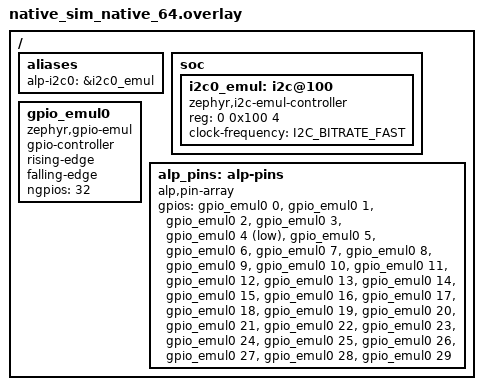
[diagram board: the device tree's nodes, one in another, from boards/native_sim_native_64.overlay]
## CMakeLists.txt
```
# SPDX-License-Identifier: Apache-2.0

cmake_minimum_required(VERSION 3.20)

# board.yaml -> build/generated/alp.conf at configure time, layered
# over prj.conf via EXTRA_CONF_FILE.  Both the emit and the append
# MUST happen before find_package(Zephyr) -- cmake/alp.cmake documents
# why, and the ALP_SDK_ROOT contract a copied-out project relies on.
if(DEFINED ENV{ALP_SDK_ROOT})
    set(ALP_SDK_ROOT $ENV{ALP_SDK_ROOT})
else()
    get_filename_component(ALP_SDK_ROOT ${CMAKE_CURRENT_SOURCE_DIR}/../../.. ABSOLUTE)
endif()
include(${ALP_SDK_ROOT}/cmake/alp.cmake)

alp_sdk_zephyr_conf(m33_sm)

find_package(Zephyr REQUIRED HINTS $ENV{ZEPHYR_BASE})
project(iot_connected_camera LANGUAGES C)

target_sources(app PRIVATE src/main.c)
```

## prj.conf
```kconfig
# SPDX-License-Identifier: Apache-2.0
#
# Intentionally empty.  Every CONFIG_* this app needs is derived
# from board.yaml by `tan build` and layered in via
# EXTRA_CONF_FILE (see scripts/gen_example_alp_conf.py).  The optional overlay
# `overlay-aen.conf` carries the v0.3 IoT stack enables; load it
# explicitly with `west build -- --extra-conf-file overlay-aen.conf`
# when targeting a real board with Wi-Fi up.

# App-specific stack tuning -- the v0.3 IoT path runs supplicant +
# mqtt loops on `main`'s frame.  Tuning, not feature-select.
CONFIG_MAIN_STACK_SIZE=4096
```

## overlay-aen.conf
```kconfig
# SPDX-License-Identifier: Apache-2.0
#
# AEN-Zephyr overlay -- enables the real Wi-Fi station + MQTT path
# for E1M-AEN family SoMs.  Layered on top of the base prj.conf via
# `west build -- -DEXTRA_CONF_FILE=overlay-aen.conf` (or twister's
# extra_args block in testcase.yaml when the EVK board file lands).
#
# native_sim builds keep the base prj.conf only -- there is no
# Wi-Fi radio under the simulator and the wrapper falls back to the
# documented NULL-with-NOSUPPORT contract.

# Networking core
CONFIG_NETWORKING=y
CONFIG_NET_TCP=y
CONFIG_NET_IPV4=y
CONFIG_NET_DHCPV4=y
CONFIG_NET_MGMT=y
CONFIG_NET_MGMT_EVENT=y
CONFIG_NET_SOCKETS=y

# Wi-Fi station (E1M-AEN ships TI CC3501E or Murata LBEE5HY2FY).
# WPA-supplicant is the upstream Zephyr Wi-Fi management default.
CONFIG_WIFI=y
CONFIG_WIFI_NM_WPA_SUPPLICANT=y

# MQTT (over plain TCP in v0.2; TLS lands with <alp/security.h> v0.3).
CONFIG_MQTT_LIB=y

# Wrapper toggles -- both default y under their CONFIG_ deps but
# spelling them out makes the intent visible to a reader who comes
# in cold.
CONFIG_ALP_SDK_IOT_WIFI=y
CONFIG_ALP_SDK_IOT_MQTT=y

# Larger main stack to absorb the Wi-Fi supplicant + mqtt loop
# threads' frames.
CONFIG_MAIN_STACK_SIZE=8192
```

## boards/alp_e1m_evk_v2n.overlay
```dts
/*
 * Copyright 2026 Alp Lab AB
 * SPDX-License-Identifier: Apache-2.0
 *
 * IoT connected-camera -- overlay for the E1M EVK populated with an
 * E1M-V2N101 / E1M-V2N102 SoM.  Re-aliases what the board file
 * exposes: alp_i2c0 (SSD1306 status pane), alp_uart0 (console), and
 * the standard POSITIONAL alp,pin-array.
 *
 * The alp,pin-array is POSITIONAL: alp_z_gpio_resolve(pin_id) indexes
 * it by the E1M GPIO index, so entry N is E1M pad N in the
 * e1m_pinout.h canonical order (IO0..IO25 = 0..25, PWM0..PWM7 =
 * 26..33, ...).  The EVK's RGB LED sits on PWM pads, so the status
 * LED is driven through a pad's GPIO-secondary index (ALP_E1M_GPIO_PWM3).
 * This overlay covers indices 0..29 -- the capture trigger is at [4]
 * and the RGB-red status LED at [29].  The EVK is shared between the
 * AEN and V2N families; only the silicon behind each pad changes.
 *
 * The authoritative alp_e1m_evk_v2n board file lives in
 * alplabai/alp-zephyr-modules (TBD); until it ships, twister excludes
 * the V2N target from the example (see testcase.yaml).
 */

#include <zephyr/dt-bindings/gpio/gpio.h>

/ {
    aliases {
        alp-i2c0  = &i2c0;       /* EVK sensor bus (SSD1306 status pane) */
        alp-uart0 = &uart0;      /* console / JTAG-side debug UART */
    };

    /* Positional alp,pin-array (e1m_pinout.h canonical order).  Only
     * the indices this demo routes carry a meaningful net; the rest
     * are placeholders so the positional index stays stable.  The gpio
     * bank/pin numbers are PLACEHOLDERS (see NOTE below). */
    alp_pins: alp-pins {
        compatible = "alp,pin-array";
        gpios = <&gpio0  0 GPIO_ACTIVE_HIGH>,                            /* [ 0] ALP_E1M_GPIO_IO0  (unrouted placeholder) */
                <&gpio0  1 GPIO_ACTIVE_HIGH>,                            /* [ 1] ALP_E1M_GPIO_IO1  (unrouted placeholder) */
                <&gpio0  2 GPIO_ACTIVE_HIGH>,                            /* [ 2] ALP_E1M_GPIO_IO2  (unrouted placeholder) */
                <&gpio0  3 GPIO_ACTIVE_HIGH>,                            /* [ 3] ALP_E1M_GPIO_IO3  (unrouted placeholder) */
                <&gpio1  0 (GPIO_ACTIVE_LOW | GPIO_PULL_UP)>,           /* [ 4] ALP_E1M_GPIO_IO4  -- capture trigger (encoder switch) */
                <&gpio0  5 GPIO_ACTIVE_HIGH>,                            /* [ 5] ALP_E1M_GPIO_IO5  (unrouted placeholder) */
                <&gpio0  6 GPIO_ACTIVE_HIGH>,                            /* [ 6] ALP_E1M_GPIO_IO6  (unrouted placeholder) */
                <&gpio0  7 GPIO_ACTIVE_HIGH>,                            /* [ 7] ALP_E1M_GPIO_IO7  (unrouted placeholder) */
                <&gpio0  8 GPIO_ACTIVE_HIGH>,                            /* [ 8] ALP_E1M_GPIO_IO8  (unrouted placeholder) */
                <&gpio0  9 GPIO_ACTIVE_HIGH>,                            /* [ 9] ALP_E1M_GPIO_IO9  (unrouted placeholder) */
                <&gpio0 10 GPIO_ACTIVE_HIGH>,                            /* [10] ALP_E1M_GPIO_IO10 (unrouted placeholder) */
                <&gpio0 11 GPIO_ACTIVE_HIGH>,                            /* [11] ALP_E1M_GPIO_IO11 (unrouted placeholder) */
                <&gpio0 12 GPIO_ACTIVE_HIGH>,                            /* [12] ALP_E1M_GPIO_IO12 (unrouted placeholder) */
                <&gpio0 13 GPIO_ACTIVE_HIGH>,                            /* [13] ALP_E1M_GPIO_IO13 (unrouted placeholder) */
                <&gpio0 14 GPIO_ACTIVE_HIGH>,                            /* [14] ALP_E1M_GPIO_IO14 (unrouted placeholder) */
                <&gpio0 15 GPIO_ACTIVE_HIGH>,                            /* [15] ALP_E1M_GPIO_IO15 (unrouted placeholder) */
                <&gpio0 16 GPIO_ACTIVE_HIGH>,                            /* [16] ALP_E1M_GPIO_IO16 (unrouted placeholder) */
                <&gpio0 17 GPIO_ACTIVE_HIGH>,                            /* [17] ALP_E1M_GPIO_IO17 (unrouted placeholder) */
                <&gpio0 18 GPIO_ACTIVE_HIGH>,                            /* [18] ALP_E1M_GPIO_IO18 (unrouted placeholder) */
                <&gpio0 19 GPIO_ACTIVE_HIGH>,                            /* [19] ALP_E1M_GPIO_IO19 (unrouted placeholder) */
                <&gpio0 20 GPIO_ACTIVE_HIGH>,                            /* [20] ALP_E1M_GPIO_IO20 (unrouted placeholder) */
                <&gpio0 21 GPIO_ACTIVE_HIGH>,                            /* [21] ALP_E1M_GPIO_IO21 (unrouted placeholder) */
                <&gpio0 22 GPIO_ACTIVE_HIGH>,                            /* [22] ALP_E1M_GPIO_IO22 (unrouted placeholder) */
                <&gpio0 23 GPIO_ACTIVE_HIGH>,                            /* [23] ALP_E1M_GPIO_IO23 (unrouted placeholder) */
                <&gpio0 24 GPIO_ACTIVE_HIGH>,                            /* [24] ALP_E1M_GPIO_IO24 (unrouted placeholder) */
                <&gpio0 25 GPIO_ACTIVE_HIGH>,                            /* [25] ALP_E1M_GPIO_IO25 (unrouted placeholder) */
                <&gpio0 26 GPIO_ACTIVE_HIGH>,                            /* [26] ALP_E1M_GPIO_PWM0 -- RGB LED green pad as GPIO */
                <&gpio0 27 GPIO_ACTIVE_HIGH>,                            /* [27] ALP_E1M_GPIO_PWM1 -- RGB LED blue pad as GPIO */
                <&gpio0 28 GPIO_ACTIVE_HIGH>,                            /* [28] ALP_E1M_GPIO_PWM2 (unrouted placeholder) */
                <&gpio1  1 GPIO_ACTIVE_HIGH>;                            /* [29] ALP_E1M_GPIO_PWM3 -- status LED (RGB-red pad as GPIO) */
    };
};

/*
 * NOTE -- gpio bank/pin numbers in the gpios property above are
 * PLACEHOLDERS.  The authoritative mapping lands when
 * alplabai/alp-zephyr-modules publishes the alp_e1m_evk_v2n board
 * file with a pinctrl group naming the exact gpio bank/index for each
 * EVK net (RGB LED on the PWM pads, encoder switch).  The POSITIONAL
 * INDEX (the [NN] in each comment) is the stable ABI; only the
 * <&gpioX Y> columns are TBD.
 */
```

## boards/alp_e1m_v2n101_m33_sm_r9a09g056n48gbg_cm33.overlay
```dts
/*
 * Copyright 2026 Alp Lab AB
 * SPDX-License-Identifier: Apache-2.0
 *
 * IoT connected-camera -- overlay for the E1M EVK populated with an
 * E1M-V2N101 / E1M-V2N102 SoM.  Re-aliases what the board file
 * exposes: alp_i2c0 (SSD1306 status pane), alp_uart0 (console), and
 * the standard POSITIONAL alp,pin-array.
 *
 * The alp,pin-array is POSITIONAL: alp_z_gpio_resolve(pin_id) indexes
 * it by the E1M GPIO index, so entry N is E1M pad N in the
 * e1m_pinout.h canonical order (IO0..IO25 = 0..25, PWM0..PWM7 =
 * 26..33, ...).  The EVK's RGB LED sits on PWM pads, so the status
 * LED is driven through a pad's GPIO-secondary index (ALP_E1M_GPIO_PWM3).
 * This overlay covers indices 0..29 -- the capture trigger is at [4]
 * and the RGB-red status LED at [29].  The EVK is shared between the
 * AEN and V2N families; only the silicon behind each pad changes.
 *
 * The authoritative alp_e1m_v2n101_m33_sm board file ships in-tree at
 * zephyr/boards/alp/e1m_v2n101_m33_sm/; the HW-in-loop scenario stays
 * parked pending twister CI wiring (see testcase.yaml).
 */

#include <zephyr/dt-bindings/gpio/gpio.h>

/ {
    aliases {
        alp-i2c0  = &i2c0;       /* EVK sensor bus (SSD1306 status pane) */
        alp-uart0 = &uart0;      /* console / JTAG-side debug UART */
    };

    /* Positional alp,pin-array (e1m_pinout.h canonical order).  Only
     * the indices this demo routes carry a meaningful net; the rest
     * are placeholders so the positional index stays stable.  The gpio
     * bank/pin numbers are PLACEHOLDERS (see NOTE below). */
    alp_pins: alp-pins {
        compatible = "alp,pin-array";
        gpios = <&gpio0  0 GPIO_ACTIVE_HIGH>,                            /* [ 0] ALP_E1M_GPIO_IO0  (unrouted placeholder) */
                <&gpio0  1 GPIO_ACTIVE_HIGH>,                            /* [ 1] ALP_E1M_GPIO_IO1  (unrouted placeholder) */
                <&gpio0  2 GPIO_ACTIVE_HIGH>,                            /* [ 2] ALP_E1M_GPIO_IO2  (unrouted placeholder) */
                <&gpio0  3 GPIO_ACTIVE_HIGH>,                            /* [ 3] ALP_E1M_GPIO_IO3  (unrouted placeholder) */
                <&gpio1  0 (GPIO_ACTIVE_LOW | GPIO_PULL_UP)>,           /* [ 4] ALP_E1M_GPIO_IO4  -- capture trigger (encoder switch) */
                <&gpio0  5 GPIO_ACTIVE_HIGH>,                            /* [ 5] ALP_E1M_GPIO_IO5  (unrouted placeholder) */
                <&gpio0  6 GPIO_ACTIVE_HIGH>,                            /* [ 6] ALP_E1M_GPIO_IO6  (unrouted placeholder) */
                <&gpio0  7 GPIO_ACTIVE_HIGH>,                            /* [ 7] ALP_E1M_GPIO_IO7  (unrouted placeholder) */
                <&gpio0  8 GPIO_ACTIVE_HIGH>,                            /* [ 8] ALP_E1M_GPIO_IO8  (unrouted placeholder) */
                <&gpio0  9 GPIO_ACTIVE_HIGH>,                            /* [ 9] ALP_E1M_GPIO_IO9  (unrouted placeholder) */
                <&gpio0 10 GPIO_ACTIVE_HIGH>,                            /* [10] ALP_E1M_GPIO_IO10 (unrouted placeholder) */
                <&gpio0 11 GPIO_ACTIVE_HIGH>,                            /* [11] ALP_E1M_GPIO_IO11 (unrouted placeholder) */
                <&gpio0 12 GPIO_ACTIVE_HIGH>,                            /* [12] ALP_E1M_GPIO_IO12 (unrouted placeholder) */
                <&gpio0 13 GPIO_ACTIVE_HIGH>,                            /* [13] ALP_E1M_GPIO_IO13 (unrouted placeholder) */
                <&gpio0 14 GPIO_ACTIVE_HIGH>,                            /* [14] ALP_E1M_GPIO_IO14 (unrouted placeholder) */
                <&gpio0 15 GPIO_ACTIVE_HIGH>,                            /* [15] ALP_E1M_GPIO_IO15 (unrouted placeholder) */
                <&gpio0 16 GPIO_ACTIVE_HIGH>,                            /* [16] ALP_E1M_GPIO_IO16 (unrouted placeholder) */
                <&gpio0 17 GPIO_ACTIVE_HIGH>,                            /* [17] ALP_E1M_GPIO_IO17 (unrouted placeholder) */
                <&gpio0 18 GPIO_ACTIVE_HIGH>,                            /* [18] ALP_E1M_GPIO_IO18 (unrouted placeholder) */
                <&gpio0 19 GPIO_ACTIVE_HIGH>,                            /* [19] ALP_E1M_GPIO_IO19 (unrouted placeholder) */
                <&gpio0 20 GPIO_ACTIVE_HIGH>,                            /* [20] ALP_E1M_GPIO_IO20 (unrouted placeholder) */
                <&gpio0 21 GPIO_ACTIVE_HIGH>,                            /* [21] ALP_E1M_GPIO_IO21 (unrouted placeholder) */
                <&gpio0 22 GPIO_ACTIVE_HIGH>,                            /* [22] ALP_E1M_GPIO_IO22 (unrouted placeholder) */
                <&gpio0 23 GPIO_ACTIVE_HIGH>,                            /* [23] ALP_E1M_GPIO_IO23 (unrouted placeholder) */
                <&gpio0 24 GPIO_ACTIVE_HIGH>,                            /* [24] ALP_E1M_GPIO_IO24 (unrouted placeholder) */
                <&gpio0 25 GPIO_ACTIVE_HIGH>,                            /* [25] ALP_E1M_GPIO_IO25 (unrouted placeholder) */
                <&gpio0 26 GPIO_ACTIVE_HIGH>,                            /* [26] ALP_E1M_GPIO_PWM0 -- RGB LED green pad as GPIO */
                <&gpio0 27 GPIO_ACTIVE_HIGH>,                            /* [27] ALP_E1M_GPIO_PWM1 -- RGB LED blue pad as GPIO */
                <&gpio0 28 GPIO_ACTIVE_HIGH>,                            /* [28] ALP_E1M_GPIO_PWM2 (unrouted placeholder) */
                <&gpio1  1 GPIO_ACTIVE_HIGH>;                            /* [29] ALP_E1M_GPIO_PWM3 -- status LED (RGB-red pad as GPIO) */
    };
};

/*
 * NOTE -- gpio bank/pin numbers in the gpios property above are
 * PLACEHOLDERS.  The authoritative mapping lands when the
 * alp_e1m_v2n101_m33_sm board file (zephyr/boards/alp/e1m_v2n101_m33_sm/)
 * grows a pinctrl group naming the exact gpio bank/index for each
 * EVK net (RGB LED on the PWM pads, encoder switch).  The POSITIONAL
 * INDEX (the [NN] in each comment) is the stable ABI; only the
 * <&gpioX Y> columns are TBD.
 */
```

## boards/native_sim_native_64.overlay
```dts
/*
 * Copyright 2026 Alp Lab AB
 * SPDX-License-Identifier: Apache-2.0
 *
 * Host-build overlay for the IoT connected-camera skeleton.  One
 * emulated I2C bus (SSD1306 status pane) plus the standard
 * alp,pin-array.  Networking is simulated via Zephyr's net stack on
 * native_sim when v0.3 lands; the v0.1 host build leaves it off.
 *
 * The alp,pin-array is POSITIONAL: alp_z_gpio_resolve(pin_id) indexes
 * it by the E1M GPIO index, so entry N must be E1M pad N in the
 * e1m_pinout.h canonical order (IO0..IO25 = 0..25, PWM0..PWM7 =
 * 26..33, ...).  This demo touches two pads through the button_led
 * block:
 *   - index  4 = ALP_E1M_GPIO_IO4   -- capture trigger (encoder switch)
 *   - index 29 = ALP_E1M_GPIO_PWM3  -- status LED, the RGB-red PWM pad
 *                claimed as a plain GPIO (the e1m-spec "GPIO
 *                secondary").
 *
 * Unlike the EVK-targeted demos, this app opens its pads by raw E1M
 * IDs rather than EVK_* macros: its target carrier's pad routes are
 * still TBD pending the schematic, so there is no board routes header
 * to name them yet.
 *
 * (gpio-emul controllers cap at 32 pins; native_sim only needs the
 * range this demo touches, indices 0..29.)
 */

#include <zephyr/dt-bindings/gpio/gpio.h>
#include <zephyr/dt-bindings/i2c/i2c.h>

/ {
    aliases {
        alp-i2c0 = &i2c0_emul;
    };

    soc {
        i2c0_emul: i2c@100 {
            compatible = "zephyr,i2c-emul-controller";
            status = "okay";
            reg = <0 0x100 4>;
            #address-cells = <1>;
            #size-cells = <0>;
            clock-frequency = <I2C_BITRATE_FAST>;
        };
    };

    gpio_emul0: gpio_emul0 {
        compatible = "zephyr,gpio-emul";
        status = "okay";
        gpio-controller;
        rising-edge;
        falling-edge;
        #gpio-cells = <2>;
        ngpios = <32>;
    };

    alp_pins: alp-pins {
        compatible = "alp,pin-array";
        gpios = <&gpio_emul0  0 GPIO_ACTIVE_HIGH>,   /* [ 0] ALP_E1M_GPIO_IO0  */
                <&gpio_emul0  1 GPIO_ACTIVE_HIGH>,   /* [ 1] ALP_E1M_GPIO_IO1  */
                <&gpio_emul0  2 GPIO_ACTIVE_HIGH>,   /* [ 2] ALP_E1M_GPIO_IO2  */
                <&gpio_emul0  3 GPIO_ACTIVE_HIGH>,   /* [ 3] ALP_E1M_GPIO_IO3  */
                <&gpio_emul0  4 (GPIO_ACTIVE_LOW | GPIO_PULL_UP)>,  /* [ 4] ALP_E1M_GPIO_IO4 -- capture trigger */
                <&gpio_emul0  5 GPIO_ACTIVE_HIGH>,   /* [ 5] ALP_E1M_GPIO_IO5  */
                <&gpio_emul0  6 GPIO_ACTIVE_HIGH>,   /* [ 6] ALP_E1M_GPIO_IO6  */
                <&gpio_emul0  7 GPIO_ACTIVE_HIGH>,   /* [ 7] ALP_E1M_GPIO_IO7  */
                <&gpio_emul0  8 GPIO_ACTIVE_HIGH>,   /* [ 8] ALP_E1M_GPIO_IO8  */
                <&gpio_emul0  9 GPIO_ACTIVE_HIGH>,   /* [ 9] ALP_E1M_GPIO_IO9  */
                <&gpio_emul0 10 GPIO_ACTIVE_HIGH>,   /* [10] ALP_E1M_GPIO_IO10 */
                <&gpio_emul0 11 GPIO_ACTIVE_HIGH>,   /* [11] ALP_E1M_GPIO_IO11 */
                <&gpio_emul0 12 GPIO_ACTIVE_HIGH>,   /* [12] ALP_E1M_GPIO_IO12 */
                <&gpio_emul0 13 GPIO_ACTIVE_HIGH>,   /* [13] ALP_E1M_GPIO_IO13 */
                <&gpio_emul0 14 GPIO_ACTIVE_HIGH>,   /* [14] ALP_E1M_GPIO_IO14 */
                <&gpio_emul0 15 GPIO_ACTIVE_HIGH>,   /* [15] ALP_E1M_GPIO_IO15 */
                <&gpio_emul0 16 GPIO_ACTIVE_HIGH>,   /* [16] ALP_E1M_GPIO_IO16 */
                <&gpio_emul0 17 GPIO_ACTIVE_HIGH>,   /* [17] ALP_E1M_GPIO_IO17 */
                <&gpio_emul0 18 GPIO_ACTIVE_HIGH>,   /* [18] ALP_E1M_GPIO_IO18 */
                <&gpio_emul0 19 GPIO_ACTIVE_HIGH>,   /* [19] ALP_E1M_GPIO_IO19 */
                <&gpio_emul0 20 GPIO_ACTIVE_HIGH>,   /* [20] ALP_E1M_GPIO_IO20 */
                <&gpio_emul0 21 GPIO_ACTIVE_HIGH>,   /* [21] ALP_E1M_GPIO_IO21 */
                <&gpio_emul0 22 GPIO_ACTIVE_HIGH>,   /* [22] ALP_E1M_GPIO_IO22 */
                <&gpio_emul0 23 GPIO_ACTIVE_HIGH>,   /* [23] ALP_E1M_GPIO_IO23 */
                <&gpio_emul0 24 GPIO_ACTIVE_HIGH>,   /* [24] ALP_E1M_GPIO_IO24 */
                <&gpio_emul0 25 GPIO_ACTIVE_HIGH>,   /* [25] ALP_E1M_GPIO_IO25 */
                <&gpio_emul0 26 GPIO_ACTIVE_HIGH>,   /* [26] ALP_E1M_GPIO_PWM0 */
                <&gpio_emul0 27 GPIO_ACTIVE_HIGH>,   /* [27] ALP_E1M_GPIO_PWM1 */
                <&gpio_emul0 28 GPIO_ACTIVE_HIGH>,   /* [28] ALP_E1M_GPIO_PWM2 */
                <&gpio_emul0 29 GPIO_ACTIVE_HIGH>;   /* [29] ALP_E1M_GPIO_PWM3 -- status LED (RGB-red pad as GPIO) */
    };
};
```

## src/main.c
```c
/*
 * Copyright 2026 Alp Lab AB
 * SPDX-License-Identifier: Apache-2.0
 *
 * IoT connected-camera reference application — v0.1 skeleton.
 *
 * Mirrors the EdgeAI vision skeleton's structure but targets the
 * V2N family for v0.3 ("IoT + display polish") rather than AEN.
 * Six stages: peripherals, camera, classifier, network, mqtt, loop.
 *
 * Each stage either runs the real v0.1 SDK call (when the surface
 * is implemented) or prints "skip" and continues so CI can verify
 * the example compiles + runs end-to-end under native_sim.  v0.2
 * and v0.3 implementations slot into the TODO blocks in-place.
 */

#include <stdio.h>

#include <zephyr/kernel.h>

#include "alp/peripheral.h"
#include "alp/board.h"
#include "alp/chips/ssd1306.h"
#include "alp/blocks/button_led.h"
#include "alp/camera.h"
#include "alp/iot.h"

/* ------------------------------------------------------------------ */
/* Stage 1 — peripherals                                               */
/* ------------------------------------------------------------------ */

static alp_i2c_t       *g_sensor_bus;
static ssd1306_t        g_oled;
static alp_button_led_t g_trigger;

static int stage_peripherals_init(void)
{
	printf("[iotcam] stage 1: peripherals\n");

	g_sensor_bus = alp_i2c_open(&(alp_i2c_config_t){
	    .bus_id     = BOARD_I2C_SENSORS,
	    .bitrate_hz = 400000,
	});
	if (g_sensor_bus == NULL) {
		printf("[iotcam]   alp_i2c_open                  failed\n");
		return -1;
	}
	printf("[iotcam]   alp_i2c_open(I2C0)            ok\n");

	alp_status_t s = ssd1306_init(&g_oled, g_sensor_bus, SSD1306_I2C_ADDR_LOW, 128, 64);
	printf("[iotcam]   ssd1306_init                  %s\n",
	       (s == ALP_OK) ? "ok" : "skip (no panel)");

	/* User trigger + status LED via the button_led block.  Board aliases
     * keep the EVK pad choices in generated route metadata instead of
     * hard-coding the E1M/E1M-X namespace in application source. */
	s = alp_button_led_init(&g_trigger,
	                        &(alp_button_led_config_t){
	                            .button_pin_id     = BOARD_PIN_ENCODER_SW,
	                            .led_pin_id        = BOARD_PIN_LED_RED,
	                            .active_low_button = true,
	                        });
	printf("[iotcam]   alp_button_led_init           %s\n",
	       (s == ALP_OK) ? "ok" : "skip (no GPIOs)");

	return 0;
}

/* ------------------------------------------------------------------ */
/* Stage 2 — camera                                                    */
/* ------------------------------------------------------------------ */

static alp_camera_t *g_camera;

static int stage_camera_init(void)
{
	printf("[iotcam] stage 2: camera\n");

	/* TODO(v0.2): open MIPI CSI-2 camera (e.g. OV5640) on the V2N
     * EVK.  RZ/V2N has 2× CSI-2 controllers (4 lanes each); the
     * V2N family routes only `CSI0_*`. */
	g_camera = alp_camera_open(&(alp_camera_config_t){
	    .camera_id = 0,
	    .width     = 320,
	    .height    = 320,
	    .fps       = 15,
	    .format    = ALP_PIXFMT_RGB888,
	});
	if (g_camera == NULL) {
		printf("[iotcam]   alp_camera_open               skip (v0.2 deliverable)\n");
	} else {
		printf("[iotcam]   alp_camera_open               ok\n");
	}
	return 0;
}

/* ------------------------------------------------------------------ */
/* Stage 3 — classifier (DRP-AI3 on V2N, Ethos-U on AEN)               */
/* ------------------------------------------------------------------ */

static int stage_classifier_load(void)
{
	printf("[iotcam] stage 3: classifier load\n");
	/* TODO(v0.2): on V2N, drop a DRP-AI-translator-compiled model
     * (`.dat`) into models/ and prime the DRP-AI3 driver via the
     * Renesas FSP.  On AEN, this is a Vela-compiled .tflite — see
     * examples/edgeai-vision-aen/.  The unified entry point for
     * both arrives in v0.3 alongside the alp_inference_* surface. */
	printf("[iotcam]   model load                    skip (v0.2 deliverable)\n");
	return 0;
}

/* ------------------------------------------------------------------ */
/* Stage 4 — networking (Wi-Fi station)                                */
/* ------------------------------------------------------------------ */

static alp_wifi_t *g_wifi;

static int stage_network_connect(void)
{
	printf("[iotcam] stage 4: network\n");
	/* TODO(v0.3): on V2N, the on-module Murata LBEE5HY2FY
	 * (Infineon CYW55513) Wi-Fi/BLE data paths are Linux-owned on
	 * the A55 Yocto slice.  On AEN Zephyr, the same portable surface
	 * resolves to the CC3501E bridge backend.  For this skeleton we
	 * just open the handle.
	 *
	 * v0.1 stub returns NULL — alp_iot_* is documented header-only
	 * surface in v0.1. */
	g_wifi = alp_wifi_open();
	if (g_wifi == NULL) {
		printf("[iotcam]   alp_wifi_open                 skip (v0.3 deliverable)\n");
		return 0;
	}
	/* On E1M-AEN801 with the CC3501E bridge attached (overlay-aen.conf), the
	 * bridge's own worst case for one STA connect is 10s Wlan_RoleUp + 30s L2
	 * association + a 30s DHCP-lease poll (hal/ti/cc3501e_hw_ti_wifi.c) = 70s.
	 * On the default V2N target (Murata LBEE5HY2FY, Linux-owned) this value
	 * is only an upper bound, not a derived worst case. */
	alp_status_t s = alp_wifi_connect(g_wifi,
	                                  &(alp_wifi_credentials_t){
	                                      .ssid = "your-ssid", /* replace with your Wi-Fi SSID */
	                                      .psk  = NULL, /* TODO(v0.3): pull from secure store */
	                                  },
	                                  75000u);
	printf("[iotcam]   alp_wifi_connect              %s\n",
	       (s == ALP_OK) ? "ok" : "skip (no station)");
	return 0;
}

/* ------------------------------------------------------------------ */
/* Stage 5 — MQTT (over TLS)                                           */
/* ------------------------------------------------------------------ */

static alp_mqtt_t *g_mqtt;

static int stage_mqtt_connect(void)
{
	printf("[iotcam] stage 5: mqtt\n");
	/* TODO(v0.3): wire MbedTLS for MQTT-over-TLS, load the CA from
     * certs/ (see certs/README.md), and connect to the broker
     * configured at build time via DTS or a CONFIG_ option.  The
     * subscribe path picks up commands; publish emits inference
     * results as JSON. */
	g_mqtt = alp_mqtt_open(&(alp_mqtt_config_t){
	    .broker_uri    = "mqtts://broker.example.com:8883",
	    .client_id     = "alp-iotcam-skeleton",
	    .keepalive_s   = 60,
	    .clean_session = true,
	});
	if (g_mqtt == NULL) {
		printf("[iotcam]   alp_mqtt_open                 skip (v0.3 deliverable)\n");
		return 0;
	}
	alp_status_t s = alp_mqtt_connect(g_mqtt, 10000);
	printf("[iotcam]   alp_mqtt_connect              %s\n",
	       (s == ALP_OK) ? "ok" : "skip (no broker)");
	return 0;
}

/* ------------------------------------------------------------------ */
/* Stage 6 — main loop                                                 */
/* ------------------------------------------------------------------ */

static int stage_main_loop(void)
{
	printf("[iotcam] stage 6: main loop\n");

	/* TODO(v0.3): the real loop —
     *
     *   while (running) {
     *       alp_camera_frame_t frame;
     *       alp_camera_capture(g_camera, &frame, 100);
     *       drpai_invoke(frame.data, &result);
     *       alp_camera_release(g_camera, &frame);
     *
     *       const char *json = format_result_json(&result);
     *       alp_mqtt_publish(g_mqtt, "alp/cam/inference",
     *                        (uint8_t *)json, strlen(json),
     *                        ALP_MQTT_QOS_1, false);
     *
     *       lvgl_render_status(&result);   // local UI
     *       alp_mqtt_loop(g_mqtt, 10);     // pump subscribe path
     *   }
     */

	/* v0.1 skeleton just touches the OLED so the SSD1306 path is
     * exercised under emul. */
	if (g_oled.initialised) {
		ssd1306_clear(&g_oled);
		for (uint16_t y = 0; y < 64; y += 8) {
			ssd1306_draw_pixel(&g_oled, 0, y, true);
			ssd1306_draw_pixel(&g_oled, 127, y, true);
		}
		(void)ssd1306_display(&g_oled);
	}

	printf("[iotcam]   main loop                     skip (v0.3 deliverable)\n");
	return 0;
}

/* ------------------------------------------------------------------ */
/* Teardown + entry                                                    */
/* ------------------------------------------------------------------ */

static void stage_teardown(void)
{
	printf("[iotcam] stage 7: teardown\n");
	alp_mqtt_close(g_mqtt);
	alp_wifi_close(g_wifi);
	if (g_camera != NULL) alp_camera_close(g_camera);
	if (g_oled.initialised) ssd1306_deinit(&g_oled);
	alp_button_led_deinit(&g_trigger);
	if (g_sensor_bus != NULL) alp_i2c_close(g_sensor_bus);
}

int main(void)
{
	printf("[iotcam] iot-connected-camera reference — v0.1 skeleton\n");

	if (stage_peripherals_init() != 0) goto done;
	if (stage_camera_init() != 0) goto done;
	if (stage_classifier_load() != 0) goto done;
	if (stage_network_connect() != 0) goto done;
	if (stage_mqtt_connect() != 0) goto done;
	if (stage_main_loop() != 0) goto done;

done:
	stage_teardown();
	printf("[iotcam] done\n");
	return 0;
}
```
